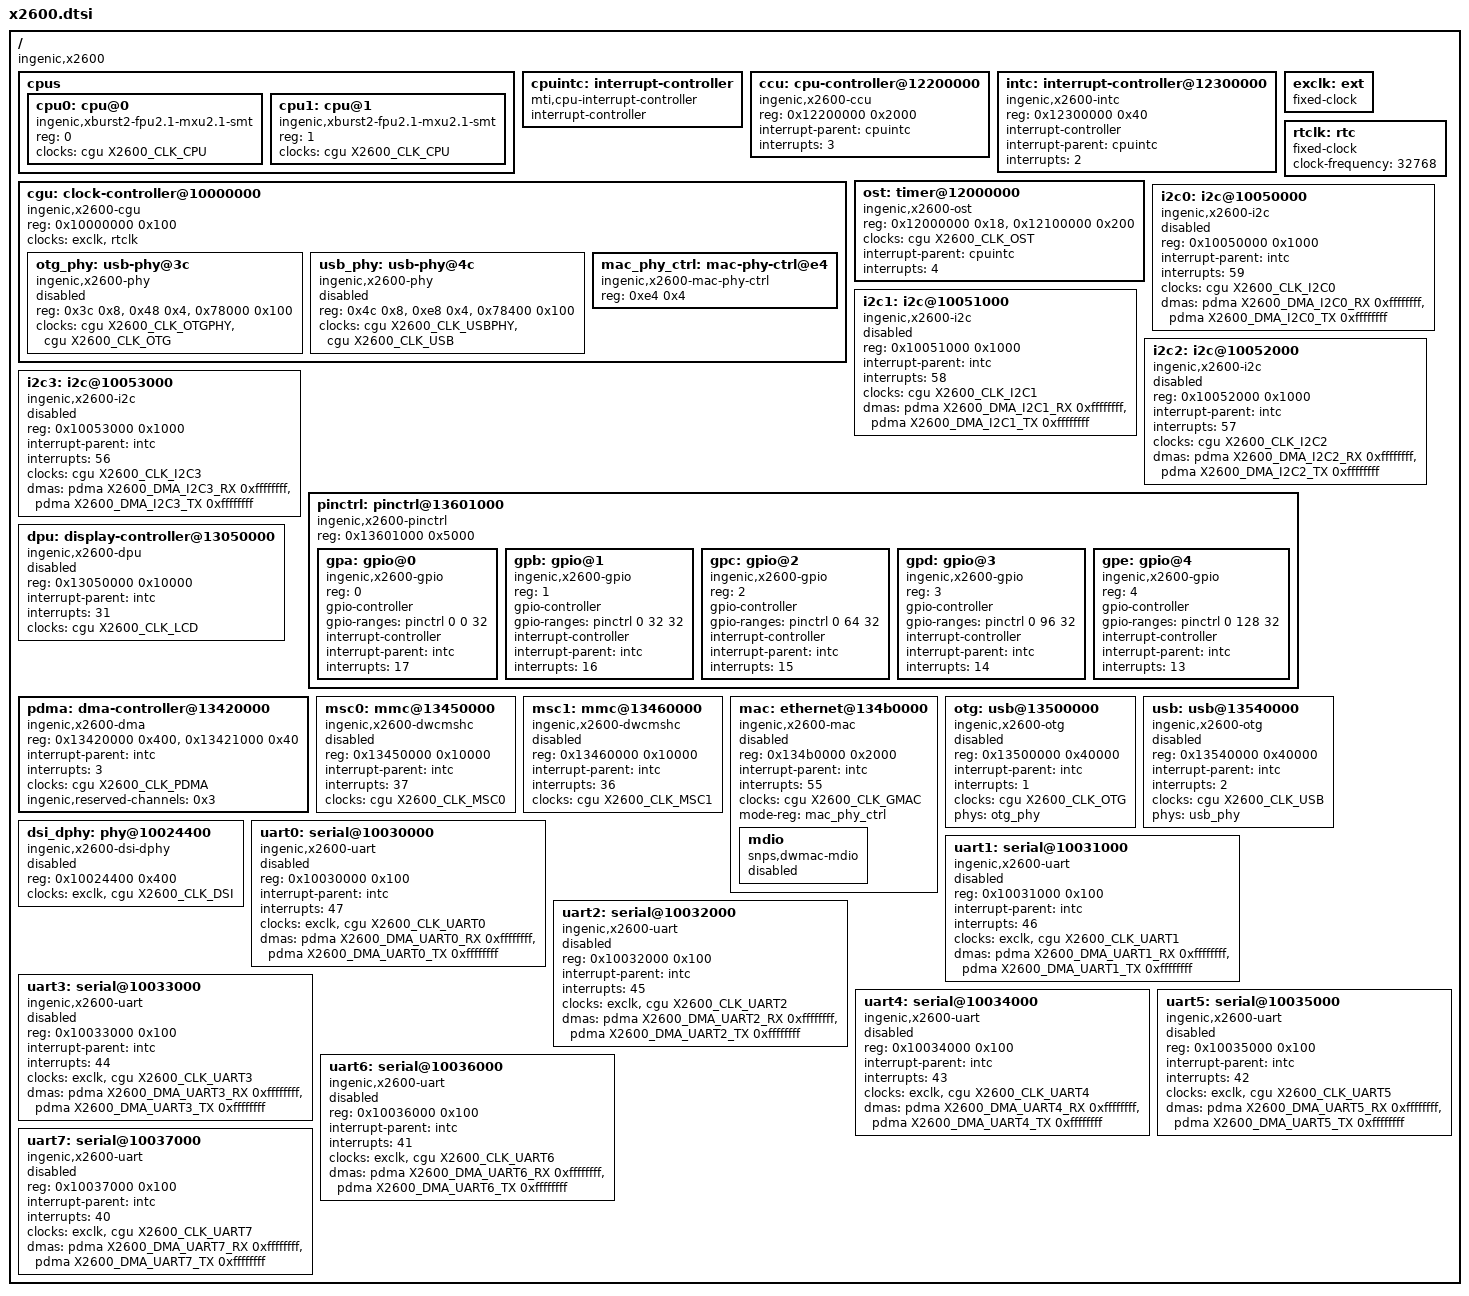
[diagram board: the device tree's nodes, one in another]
// SPDX-License-Identifier: GPL-2.0
#include <dt-bindings/clock/ingenic,x2600-cgu.h>
#include <dt-bindings/dma/ingenic,x2600-dma.h>

/ {
	#address-cells = <1>;
	#size-cells = <1>;
	compatible = "ingenic,x2600";

	cpus {
		#address-cells = <1>;
		#size-cells = <0>;

		cpu0: cpu@0 {
			device_type = "cpu";
			compatible = "ingenic,xburst2-fpu2.1-mxu2.1-smt";
			reg = <0>;

			clocks = <&cgu X2600_CLK_CPU>;
		};

		cpu1: cpu@1 {
			device_type = "cpu";
			compatible = "ingenic,xburst2-fpu2.1-mxu2.1-smt";
			reg = <1>;

			clocks = <&cgu X2600_CLK_CPU>;
		};
	};

	cpuintc: interrupt-controller {
		#address-cells = <0>;
		#interrupt-cells = <1>;
		interrupt-controller;
		compatible = "mti,cpu-interrupt-controller";
	};

	ccu: cpu-controller@12200000 {
		compatible = "ingenic,x2600-ccu";
		reg = <0x12200000 0x2000>;

		interrupt-parent = <&cpuintc>;
		interrupts = <3>;
	};

	/* The bank of CPU 0; each core has its own, 0x100 apart */
	intc: interrupt-controller@12300000 {
		compatible = "ingenic,x2600-intc", "ingenic,jz4780-intc";
		reg = <0x12300000 0x40>;

		interrupt-controller;
		#interrupt-cells = <1>;

		interrupt-parent = <&cpuintc>;
		interrupts = <2>;
	};

	exclk: ext {
		compatible = "fixed-clock";
		#clock-cells = <0>;
	};

	rtclk: rtc {
		compatible = "fixed-clock";
		#clock-cells = <0>;
		clock-frequency = <32768>;
	};

	cgu: clock-controller@10000000 {
		compatible = "ingenic,x2600-cgu", "simple-mfd";
		reg = <0x10000000 0x100>;
		#address-cells = <1>;
		#size-cells = <1>;
		ranges = <0x0 0x10000000 0x100>,
			 <0x78000 0x10078000 0x800>;

		#clock-cells = <1>;

		clocks = <&exclk>, <&rtclk>;
		clock-names = "ext", "rtc";

		otg_phy: usb-phy@3c {
			compatible = "ingenic,x2600-phy";
			reg = <0x3c 0x8>, <0x48 0x4>, <0x78000 0x100>;

			clocks = <&cgu X2600_CLK_OTGPHY>, <&cgu X2600_CLK_OTG>;
			clock-names = "phy", "bus";

			#phy-cells = <0>;

			status = "disabled";
		};

		usb_phy: usb-phy@4c {
			compatible = "ingenic,x2600-phy";
			reg = <0x4c 0x8>, <0xe8 0x4>, <0x78400 0x100>;

			clocks = <&cgu X2600_CLK_USBPHY>, <&cgu X2600_CLK_USB>;
			clock-names = "phy", "bus";

			#phy-cells = <0>;

			status = "disabled";
		};

		mac_phy_ctrl: mac-phy-ctrl@e4 {
			compatible = "ingenic,x2600-mac-phy-ctrl", "syscon";
			reg = <0xe4 0x4>;
		};
	};

	ost: timer@12000000 {
		compatible = "ingenic,x2600-ost";
		reg = <0x12000000 0x18>, <0x12100000 0x200>;
		reg-names = "global", "core";

		clocks = <&cgu X2600_CLK_OST>;
		clock-names = "ost";

		interrupt-parent = <&cpuintc>;
		interrupts = <4>;
	};

	i2c0: i2c@10050000 {
		compatible = "ingenic,x2600-i2c", "ingenic,x1000-i2c";
		reg = <0x10050000 0x1000>;
		#address-cells = <1>;
		#size-cells = <0>;

		interrupt-parent = <&intc>;
		interrupts = <59>;

		clocks = <&cgu X2600_CLK_I2C0>;

		dmas = <&pdma X2600_DMA_I2C0_RX 0xffffffff>,
		       <&pdma X2600_DMA_I2C0_TX 0xffffffff>;
		dma-names = "rx", "tx";

		status = "disabled";
	};

	i2c1: i2c@10051000 {
		compatible = "ingenic,x2600-i2c", "ingenic,x1000-i2c";
		reg = <0x10051000 0x1000>;
		#address-cells = <1>;
		#size-cells = <0>;

		interrupt-parent = <&intc>;
		interrupts = <58>;

		clocks = <&cgu X2600_CLK_I2C1>;

		dmas = <&pdma X2600_DMA_I2C1_RX 0xffffffff>,
		       <&pdma X2600_DMA_I2C1_TX 0xffffffff>;
		dma-names = "rx", "tx";

		status = "disabled";
	};

	i2c2: i2c@10052000 {
		compatible = "ingenic,x2600-i2c", "ingenic,x1000-i2c";
		reg = <0x10052000 0x1000>;
		#address-cells = <1>;
		#size-cells = <0>;

		interrupt-parent = <&intc>;
		interrupts = <57>;

		clocks = <&cgu X2600_CLK_I2C2>;

		dmas = <&pdma X2600_DMA_I2C2_RX 0xffffffff>,
		       <&pdma X2600_DMA_I2C2_TX 0xffffffff>;
		dma-names = "rx", "tx";

		status = "disabled";
	};

	i2c3: i2c@10053000 {
		compatible = "ingenic,x2600-i2c", "ingenic,x1000-i2c";
		reg = <0x10053000 0x1000>;
		#address-cells = <1>;
		#size-cells = <0>;

		interrupt-parent = <&intc>;
		interrupts = <56>;

		clocks = <&cgu X2600_CLK_I2C3>;

		dmas = <&pdma X2600_DMA_I2C3_RX 0xffffffff>,
		       <&pdma X2600_DMA_I2C3_TX 0xffffffff>;
		dma-names = "rx", "tx";

		status = "disabled";
	};

	pinctrl: pinctrl@13601000 {
		compatible = "ingenic,x2600-pinctrl";
		reg = <0x13601000 0x5000>;
		#address-cells = <1>;
		#size-cells = <0>;

		gpa: gpio@0 {
			compatible = "ingenic,x2600-gpio";
			reg = <0>;

			gpio-controller;
			gpio-ranges = <&pinctrl 0 0 32>;
			#gpio-cells = <2>;

			interrupt-controller;
			#interrupt-cells = <2>;

			interrupt-parent = <&intc>;
			interrupts = <17>;
		};

		gpb: gpio@1 {
			compatible = "ingenic,x2600-gpio";
			reg = <1>;

			gpio-controller;
			gpio-ranges = <&pinctrl 0 32 32>;
			#gpio-cells = <2>;

			interrupt-controller;
			#interrupt-cells = <2>;

			interrupt-parent = <&intc>;
			interrupts = <16>;
		};

		gpc: gpio@2 {
			compatible = "ingenic,x2600-gpio";
			reg = <2>;

			gpio-controller;
			gpio-ranges = <&pinctrl 0 64 32>;
			#gpio-cells = <2>;

			interrupt-controller;
			#interrupt-cells = <2>;

			interrupt-parent = <&intc>;
			interrupts = <15>;
		};

		gpd: gpio@3 {
			compatible = "ingenic,x2600-gpio";
			reg = <3>;

			gpio-controller;
			gpio-ranges = <&pinctrl 0 96 32>;
			#gpio-cells = <2>;

			interrupt-controller;
			#interrupt-cells = <2>;

			interrupt-parent = <&intc>;
			interrupts = <14>;
		};

		gpe: gpio@4 {
			compatible = "ingenic,x2600-gpio";
			reg = <4>;

			gpio-controller;
			gpio-ranges = <&pinctrl 0 128 32>;
			#gpio-cells = <2>;

			interrupt-controller;
			#interrupt-cells = <2>;

			interrupt-parent = <&intc>;
			interrupts = <13>;
		};
	};

	dpu: display-controller@13050000 {
		compatible = "ingenic,x2600-dpu";
		reg = <0x13050000 0x10000>;

		interrupt-parent = <&intc>;
		interrupts = <31>;

		clocks = <&cgu X2600_CLK_LCD>;
		clock-names = "lcd";

		status = "disabled";
	};

	pdma: dma-controller@13420000 {
		compatible = "ingenic,x2600-dma", "ingenic,x1830-dma";
		reg = <0x13420000 0x400>, <0x13421000 0x40>;

		#dma-cells = <2>;

		interrupt-parent = <&intc>;
		interrupts = <3>;

		clocks = <&cgu X2600_CLK_PDMA>;

		/* Channels 0 and 1 can be run by the PDMA's own MCU */
		ingenic,reserved-channels = <0x3>;
	};

	msc0: mmc@13450000 {
		compatible = "ingenic,x2600-dwcmshc";
		reg = <0x13450000 0x10000>;

		interrupt-parent = <&intc>;
		interrupts = <37>;

		clocks = <&cgu X2600_CLK_MSC0>;
		clock-names = "core";

		status = "disabled";
	};

	msc1: mmc@13460000 {
		compatible = "ingenic,x2600-dwcmshc";
		reg = <0x13460000 0x10000>;

		interrupt-parent = <&intc>;
		interrupts = <36>;

		clocks = <&cgu X2600_CLK_MSC1>;
		clock-names = "core";

		status = "disabled";
	};

	mac: ethernet@134b0000 {
		compatible = "ingenic,x2600-mac", "ingenic,x1000-mac", "snps,dwmac";
		reg = <0x134b0000 0x2000>;

		interrupt-parent = <&intc>;
		interrupts = <55>;
		interrupt-names = "macirq";

		clocks = <&cgu X2600_CLK_GMAC>;
		clock-names = "stmmaceth";

		mode-reg = <&mac_phy_ctrl>;

		status = "disabled";

		mdio: mdio {
			compatible = "snps,dwmac-mdio";
			#address-cells = <1>;
			#size-cells = <0>;

			status = "disabled";
		};
	};

	otg: usb@13500000 {
		compatible = "ingenic,x2600-otg", "ingenic,x2000-otg";
		reg = <0x13500000 0x40000>;

		interrupt-parent = <&intc>;
		interrupts = <1>;

		clocks = <&cgu X2600_CLK_OTG>;
		clock-names = "otg";

		phys = <&otg_phy>;
		phy-names = "usb2-phy";

		status = "disabled";
	};

	usb: usb@13540000 {
		compatible = "ingenic,x2600-otg", "ingenic,x2000-otg";
		reg = <0x13540000 0x40000>;

		interrupt-parent = <&intc>;
		interrupts = <2>;

		clocks = <&cgu X2600_CLK_USB>;
		clock-names = "otg";

		phys = <&usb_phy>;
		phy-names = "usb2-phy";

		status = "disabled";
	};

	/* The Innosilicon PHY's registers start 0x400 into the MIPI TX PHY block */
	dsi_dphy: phy@10024400 {
		compatible = "ingenic,x2600-dsi-dphy";
		reg = <0x10024400 0x400>;

		clocks = <&exclk>, <&cgu X2600_CLK_DSI>;
		clock-names = "ref", "pclk";

		#phy-cells = <0>;

		status = "disabled";
	};

	uart0: serial@10030000 {
		compatible = "ingenic,x2600-uart", "ingenic,x1000-uart";
		reg = <0x10030000 0x100>;

		interrupt-parent = <&intc>;
		interrupts = <47>;

		clocks = <&exclk>, <&cgu X2600_CLK_UART0>;
		clock-names = "baud", "module";

		dmas = <&pdma X2600_DMA_UART0_RX 0xffffffff>,
		       <&pdma X2600_DMA_UART0_TX 0xffffffff>;
		dma-names = "rx", "tx";

		status = "disabled";
	};

	uart1: serial@10031000 {
		compatible = "ingenic,x2600-uart", "ingenic,x1000-uart";
		reg = <0x10031000 0x100>;

		interrupt-parent = <&intc>;
		interrupts = <46>;

		clocks = <&exclk>, <&cgu X2600_CLK_UART1>;
		clock-names = "baud", "module";

		dmas = <&pdma X2600_DMA_UART1_RX 0xffffffff>,
		       <&pdma X2600_DMA_UART1_TX 0xffffffff>;
		dma-names = "rx", "tx";

		status = "disabled";
	};

	uart2: serial@10032000 {
		compatible = "ingenic,x2600-uart", "ingenic,x1000-uart";
		reg = <0x10032000 0x100>;

		interrupt-parent = <&intc>;
		interrupts = <45>;

		clocks = <&exclk>, <&cgu X2600_CLK_UART2>;
		clock-names = "baud", "module";

		dmas = <&pdma X2600_DMA_UART2_RX 0xffffffff>,
		       <&pdma X2600_DMA_UART2_TX 0xffffffff>;
		dma-names = "rx", "tx";

		status = "disabled";
	};

	uart3: serial@10033000 {
		compatible = "ingenic,x2600-uart", "ingenic,x1000-uart";
		reg = <0x10033000 0x100>;

		interrupt-parent = <&intc>;
		interrupts = <44>;

		clocks = <&exclk>, <&cgu X2600_CLK_UART3>;
		clock-names = "baud", "module";

		dmas = <&pdma X2600_DMA_UART3_RX 0xffffffff>,
		       <&pdma X2600_DMA_UART3_TX 0xffffffff>;
		dma-names = "rx", "tx";

		status = "disabled";
	};

	uart4: serial@10034000 {
		compatible = "ingenic,x2600-uart", "ingenic,x1000-uart";
		reg = <0x10034000 0x100>;

		interrupt-parent = <&intc>;
		interrupts = <43>;

		clocks = <&exclk>, <&cgu X2600_CLK_UART4>;
		clock-names = "baud", "module";

		dmas = <&pdma X2600_DMA_UART4_RX 0xffffffff>,
		       <&pdma X2600_DMA_UART4_TX 0xffffffff>;
		dma-names = "rx", "tx";

		status = "disabled";
	};

	uart5: serial@10035000 {
		compatible = "ingenic,x2600-uart", "ingenic,x1000-uart";
		reg = <0x10035000 0x100>;

		interrupt-parent = <&intc>;
		interrupts = <42>;

		clocks = <&exclk>, <&cgu X2600_CLK_UART5>;
		clock-names = "baud", "module";

		dmas = <&pdma X2600_DMA_UART5_RX 0xffffffff>,
		       <&pdma X2600_DMA_UART5_TX 0xffffffff>;
		dma-names = "rx", "tx";

		status = "disabled";
	};

	uart6: serial@10036000 {
		compatible = "ingenic,x2600-uart", "ingenic,x1000-uart";
		reg = <0x10036000 0x100>;

		interrupt-parent = <&intc>;
		interrupts = <41>;

		clocks = <&exclk>, <&cgu X2600_CLK_UART6>;
		clock-names = "baud", "module";

		dmas = <&pdma X2600_DMA_UART6_RX 0xffffffff>,
		       <&pdma X2600_DMA_UART6_TX 0xffffffff>;
		dma-names = "rx", "tx";

		status = "disabled";
	};

	uart7: serial@10037000 {
		compatible = "ingenic,x2600-uart", "ingenic,x1000-uart";
		reg = <0x10037000 0x100>;

		interrupt-parent = <&intc>;
		interrupts = <40>;

		clocks = <&exclk>, <&cgu X2600_CLK_UART7>;
		clock-names = "baud", "module";

		dmas = <&pdma X2600_DMA_UART7_RX 0xffffffff>,
		       <&pdma X2600_DMA_UART7_TX 0xffffffff>;
		dma-names = "rx", "tx";

		status = "disabled";
	};
};
